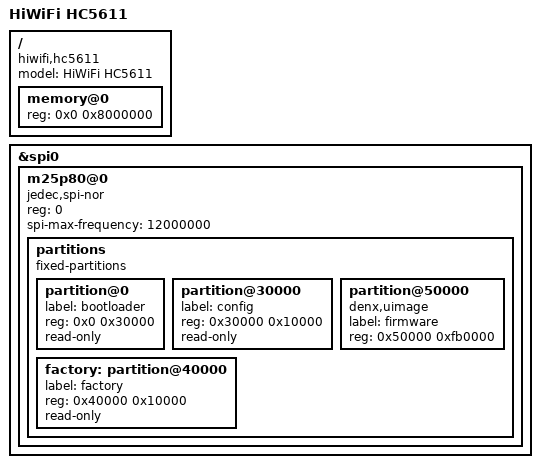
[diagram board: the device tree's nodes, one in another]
/dts-v1/;

#include "U7628-01.dtsi"

/ {
	compatible = "hiwifi,hc5611", "mediatek,mt7628an-soc";
	model = "HiWiFi HC5611";

	memory@0 {
		device_type = "memory";
		reg = <0x0 0x8000000>;
	};
};

&spi0 {
	status = "okay";

	m25p80@0 {
		compatible = "jedec,spi-nor";
		reg = <0>;
		spi-max-frequency = <12000000>;

		partitions {
			compatible = "fixed-partitions";
			#address-cells = <1>;
			#size-cells = <1>;

			partition@0 {
				label = "bootloader";
				reg = <0x0 0x30000>;
				read-only;
			};

			partition@30000 {
				label = "config";
				reg = <0x30000 0x10000>;
				read-only;
			};

			factory: partition@40000 {
				label = "factory";
				reg = <0x40000 0x10000>;
				read-only;
			};

			partition@50000 {
				compatible = "denx,uimage";
				label = "firmware";
				reg = <0x50000 0xfb0000>;
			};
		};
	};
};
